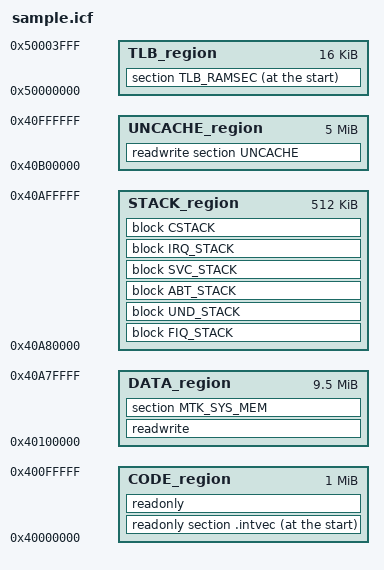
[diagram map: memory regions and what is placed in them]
/* AP-RZG-0A CPU0 micro T-Kernel RAM-download layout. */
define symbol __region_CODE_start__     = 0x40000000;
define symbol __region_CODE_end__       = 0x400FFFFF;
define symbol __region_DATA_start__     = 0x40100000;
define symbol __region_DATA_end__       = 0x40A7FFFF;
define symbol __region_STACK_start__    = 0x40A80000;
define symbol __region_STACK_end__      = 0x40AFFFFF;
define symbol __region_UNCACHE_start__  = 0x40B00000;
define symbol __region_UNCACHE_end__    = 0x40FFFFFF;
define symbol __region_TLB_start__      = 0x50000000;
define symbol __region_TLB_end__        = 0x50003FFF;

define symbol __size_cstack__   = 0x8000;
define symbol __size_svcstack__ = 0x1000;
define symbol __size_irqstack__ = 0x1000;
define symbol __size_fiqstack__ = 0x0400;
define symbol __size_undstack__ = 0x0400;
define symbol __size_abtstack__ = 0x0400;

define memory mem with size = 4G;

define region CODE_region = mem:[from __region_CODE_start__ to __region_CODE_end__];
define region DATA_region = mem:[from __region_DATA_start__ to __region_DATA_end__];
define region STACK_region = mem:[from __region_STACK_start__ to __region_STACK_end__];
define region UNCACHE_region = mem:[from __region_UNCACHE_start__ to __region_UNCACHE_end__];
define region TLB_region = mem:[from __region_TLB_start__ to __region_TLB_end__];

define block CSTACK with alignment = 8, size = __size_cstack__ { };
define block SVC_STACK with alignment = 8, size = __size_svcstack__ { };
define block IRQ_STACK with alignment = 8, size = __size_irqstack__ { };
define block FIQ_STACK with alignment = 8, size = __size_fiqstack__ { };
define block UND_STACK with alignment = 8, size = __size_undstack__ { };
define block ABT_STACK with alignment = 8, size = __size_abtstack__ { };

initialize by copy { readwrite };
do not initialize { section .noinit };

place at start of CODE_region { readonly section .intvec };
place in CODE_region { readonly };
place in DATA_region { readwrite, section MTK_SYS_MEM };
place in STACK_region {
    block FIQ_STACK,
    block UND_STACK,
    block ABT_STACK,
    block SVC_STACK,
    block IRQ_STACK,
    block CSTACK
};
place in UNCACHE_region { readwrite section UNCACHE };
place at start of TLB_region { section TLB_RAMSEC };
